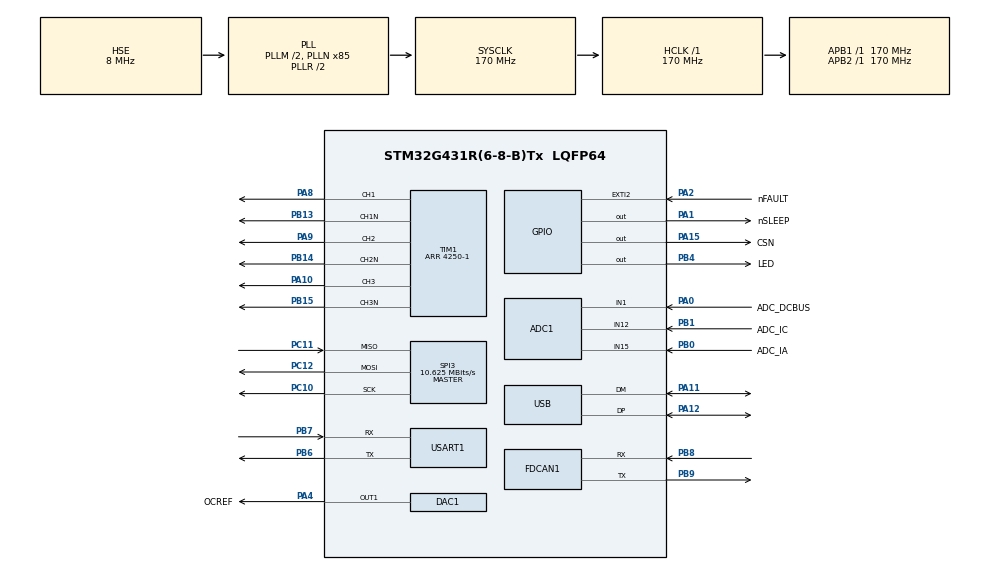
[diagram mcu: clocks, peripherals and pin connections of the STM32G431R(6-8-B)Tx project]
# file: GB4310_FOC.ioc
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ADC1.Channel-4\#ChannelRegularConversion=ADC_CHANNEL_1
ADC1.Channel-5\#ChannelRegularConversion=ADC_CHANNEL_VREFINT
ADC1.DMAContinuousRequests=ENABLE
ADC1.EOCSelection=ADC_EOC_SINGLE_CONV
ADC1.EnableInjectedConversion=ENABLE
ADC1.EnableRegularConversion=ENABLE
ADC1.ExternalTrigConv=ADC_EXTERNALTRIG_T7_TRGO
ADC1.ExternalTrigConvEdge=ADC_EXTERNALTRIGCONVEDGE_RISING
ADC1.ExternalTrigInjecConv=ADC_EXTERNALTRIGINJEC_T1_CC4
ADC1.ExternalTrigInjecConvEdge=ADC_EXTERNALTRIGINJECCONV_EDGE_FALLING
ADC1.InjNumberOfConversion=2
ADC1.InjectedChannel-1\#ChannelInjectedConversion=ADC_CHANNEL_15
ADC1.InjectedChannel-2\#ChannelInjectedConversion=ADC_CHANNEL_12
ADC1.InjectedOffsetNumber-1\#ChannelInjectedConversion=ADC_OFFSET_NONE
ADC1.InjectedOffsetNumber-2\#ChannelInjectedConversion=ADC_OFFSET_NONE
ADC1.InjectedRank-1\#ChannelInjectedConversion=1
ADC1.InjectedRank-2\#ChannelInjectedConversion=2
ADC1.InjectedSamplingTime-1\#ChannelInjectedConversion=ADC_SAMPLETIME_2CYCLES_5
ADC1.InjectedSamplingTime-2\#ChannelInjectedConversion=ADC_SAMPLETIME_2CYCLES_5
ADC1.NbrOfConversion=2
ADC1.NbrOfConversionFlag=1
ADC1.OffsetNumber-4\#ChannelRegularConversion=ADC_OFFSET_NONE
ADC1.OffsetNumber-5\#ChannelRegularConversion=ADC_OFFSET_NONE
ADC1.Rank-4\#ChannelRegularConversion=1
ADC1.Rank-5\#ChannelRegularConversion=2
ADC1.Rank1_Channel=ADC_CHANNEL_15
ADC1.SamplingTime-4\#ChannelRegularConversion=ADC_SAMPLETIME_247CYCLES_5
ADC1.SamplingTime-5\#ChannelRegularConversion=ADC_SAMPLETIME_247CYCLES_5
ADC1.master=1
CRC.CRCLength=CRC_POLYLENGTH_8B
CRC.DefaultInitValueUse=DEFAULT_INIT_VALUE_DISABLE
CRC.DefaultPolynomialUse=DEFAULT_POLYNOMIAL_DISABLE
CRC.InputDataInversionMode=CRC_INPUTDATA_INVERSION_NONE
DAC1.DAC_HighFrequency_OUT1-DAC_OUT1=DAC_HIGH_FREQUENCY_INTERFACE_MODE_AUTOMATIC
DAC1.DAC_OutputBuffer-DAC_OUT1=DAC_OUTPUTBUFFER_DISABLE
DAC1.DAC_SampleAndHold-DAC_OUT1=DAC_SAMPLEANDHOLD_DISABLE
DAC1.DAC_Trigger_OUT1-DAC_OUT1=DAC_TRIGGER_NONE
Dma.ADC1.4.Direction=DMA_PERIPH_TO_MEMORY
Dma.ADC1.4.EventEnable=DISABLE
Dma.ADC1.4.Instance=DMA1_Channel5
Dma.ADC1.4.MemDataAlignment=DMA_MDATAALIGN_HALFWORD
Dma.ADC1.4.MemInc=DMA_MINC_ENABLE
Dma.ADC1.4.Mode=DMA_CIRCULAR
Dma.ADC1.4.PeriphDataAlignment=DMA_PDATAALIGN_HALFWORD
Dma.ADC1.4.PeriphInc=DMA_PINC_DISABLE
Dma.ADC1.4.Polarity=HAL_DMAMUX_REQ_GEN_RISING
Dma.ADC1.4.Priority=DMA_PRIORITY_VERY_HIGH
Dma.ADC1.4.RequestNumber=1
Dma.ADC1.4.SignalID=NONE
Dma.ADC1.4.SyncEnable=DISABLE
Dma.ADC1.4.SyncPolarity=HAL_DMAMUX_SYNC_NO_EVENT
Dma.ADC1.4.SyncRequestNumber=1
Dma.ADC1.4.SyncSignalID=NONE
Dma.Request0=USART1_TX
Dma.Request1=USART1_RX
Dma.Request2=SPI3_TX
Dma.Request3=SPI3_RX
Dma.Request4=ADC1
Dma.SPI3_RX.3.Direction=DMA_PERIPH_TO_MEMORY
Dma.SPI3_RX.3.EventEnable=DISABLE
Dma.SPI3_RX.3.Instance=DMA1_Channel4
Dma.SPI3_RX.3.MemDataAlignment=DMA_MDATAALIGN_BYTE
Dma.SPI3_RX.3.MemInc=DMA_MINC_ENABLE
Dma.SPI3_RX.3.Mode=DMA_NORMAL
Dma.SPI3_RX.3.PeriphDataAlignment=DMA_PDATAALIGN_BYTE
Dma.SPI3_RX.3.PeriphInc=DMA_PINC_DISABLE
Dma.SPI3_RX.3.Polarity=HAL_DMAMUX_REQ_GEN_RISING
Dma.SPI3_RX.3.Priority=DMA_PRIORITY_HIGH
Dma.SPI3_RX.3.RequestNumber=1
Dma.SPI3_RX.3.SignalID=NONE
Dma.SPI3_RX.3.SyncEnable=DISABLE
Dma.SPI3_RX.3.SyncPolarity=HAL_DMAMUX_SYNC_NO_EVENT
Dma.SPI3_RX.3.SyncRequestNumber=1
Dma.SPI3_RX.3.SyncSignalID=NONE
Dma.SPI3_TX.2.Direction=DMA_MEMORY_TO_PERIPH
Dma.SPI3_TX.2.EventEnable=DISABLE
Dma.SPI3_TX.2.Instance=DMA1_Channel3
Dma.SPI3_TX.2.MemDataAlignment=DMA_MDATAALIGN_BYTE
Dma.SPI3_TX.2.MemInc=DMA_MINC_ENABLE
Dma.SPI3_TX.2.Mode=DMA_NORMAL
Dma.SPI3_TX.2.PeriphDataAlignment=DMA_PDATAALIGN_BYTE
Dma.SPI3_TX.2.PeriphInc=DMA_PINC_DISABLE
Dma.SPI3_TX.2.Polarity=HAL_DMAMUX_REQ_GEN_RISING
Dma.SPI3_TX.2.Priority=DMA_PRIORITY_HIGH
Dma.SPI3_TX.2.RequestNumber=1
Dma.SPI3_TX.2.SignalID=NONE
Dma.SPI3_TX.2.SyncEnable=DISABLE
Dma.SPI3_TX.2.SyncPolarity=HAL_DMAMUX_SYNC_NO_EVENT
Dma.SPI3_TX.2.SyncRequestNumber=1
Dma.SPI3_TX.2.SyncSignalID=NONE
Dma.USART1_RX.1.Direction=DMA_PERIPH_TO_MEMORY
Dma.USART1_RX.1.EventEnable=DISABLE
Dma.USART1_RX.1.Instance=DMA1_Channel2
Dma.USART1_RX.1.MemDataAlignment=DMA_MDATAALIGN_BYTE
Dma.USART1_RX.1.MemInc=DMA_MINC_ENABLE
Dma.USART1_RX.1.Mode=DMA_NORMAL
Dma.USART1_RX.1.PeriphDataAlignment=DMA_PDATAALIGN_BYTE
Dma.USART1_RX.1.PeriphInc=DMA_PINC_DISABLE
Dma.USART1_RX.1.Polarity=HAL_DMAMUX_REQ_GEN_RISING
Dma.USART1_RX.1.Priority=DMA_PRIORITY_LOW
Dma.USART1_RX.1.RequestNumber=1
Dma.USART1_RX.1.SignalID=NONE
Dma.USART1_RX.1.SyncEnable=DISABLE
Dma.USART1_RX.1.SyncPolarity=HAL_DMAMUX_SYNC_NO_EVENT
Dma.USART1_RX.1.SyncRequestNumber=1
Dma.USART1_RX.1.SyncSignalID=NONE
Dma.USART1_TX.0.Direction=DMA_MEMORY_TO_PERIPH
Dma.USART1_TX.0.EventEnable=DISABLE
Dma.USART1_TX.0.Instance=DMA1_Channel1
Dma.USART1_TX.0.MemDataAlignment=DMA_MDATAALIGN_BYTE
Dma.USART1_TX.0.MemInc=DMA_MINC_ENABLE
Dma.USART1_TX.0.Mode=DMA_NORMAL
Dma.USART1_TX.0.PeriphDataAlignment=DMA_PDATAALIGN_BYTE
Dma.USART1_TX.0.PeriphInc=DMA_PINC_DISABLE
Dma.USART1_TX.0.Polarity=HAL_DMAMUX_REQ_GEN_RISING
Dma.USART1_TX.0.Priority=DMA_PRIORITY_LOW
Dma.USART1_TX.0.RequestNumber=1
Dma.USART1_TX.0.SignalID=NONE
Dma.USART1_TX.0.SyncEnable=DISABLE
Dma.USART1_TX.0.SyncPolarity=HAL_DMAMUX_SYNC_NO_EVENT
Dma.USART1_TX.0.SyncRequestNumber=1
Dma.USART1_TX.0.SyncSignalID=NONE
FDCAN1.CalculateBaudRateNominal=3541666
FDCAN1.CalculateTimeBitNominal=282
FDCAN1.CalculateTimeQuantumNominal=94.11764705882354
Mcu.Family=STM32G4
Mcu.Name=STM32G431R(6-8-B)Tx
Mcu.Package=LQFP64
NVIC.ADC1_2_IRQn=true\:1\:0\:true\:false\:true\:true\:true\:true
NVIC.DMA1_Channel3_IRQn=true\:4\:0\:true\:false\:true\:false\:true\:true
NVIC.DMA1_Channel4_IRQn=true\:4\:0\:true\:false\:true\:false\:true\:true
NVIC.DMA1_Channel5_IRQn=true\:2\:0\:true\:false\:true\:true\:true\:true
NVIC.EXTI2_IRQn=true\:0\:0\:false\:false\:true\:true\:true\:true
NVIC.PriorityGroup=NVIC_PRIORITYGROUP_4
NVIC.TIM1_CC_IRQn=true\:4\:0\:true\:false\:true\:true\:true\:true
NVIC.TIM1_UP_TIM16_IRQn=true\:3\:0\:true\:false\:true\:true\:true\:true
NVIC.TIM7_IRQn=true\:5\:0\:true\:false\:true\:true\:true\:true
NVIC.USB_LP_IRQn=true\:6\:0\:true\:false\:true\:false\:true\:true
PA0.GPIO_Label=ADC_DCBUS
PA0.Mode=IN1-Single-Ended
PA0.Signal=ADC1_IN1
PA1.GPIO_Label=nSLEEP
PA1.GPIO_PuPd=GPIO_NOPULL
PA1.PinState=GPIO_PIN_RESET
PA1.Signal=GPIO_Output
PA10.Signal=S_TIM1_CH3
PA11.Mode=Device
PA11.Signal=USB_DM
PA12.Mode=Device
PA12.Signal=USB_DP
PA13.Mode=Serial_Wire
PA13.Signal=SYS_JTMS-SWDIO
PA14.Mode=Serial_Wire
PA14.Signal=SYS_JTCK-SWCLK
PA15.GPIO_Label=CSN
PA15.GPIO_PuPd=GPIO_PULLUP
PA15.PinState=GPIO_PIN_SET
PA15.Signal=GPIO_Output
PA2.GPIO_Label=nFAULT
PA2.GPIO_ModeDefaultEXTI=GPIO_MODE_IT_FALLING
PA2.GPIO_PuPd=GPIO_PULLUP
PA2.Signal=GPXTI2
PA4.GPIO_Label=OCREF
PA4.Signal=COMP_DAC11_group
PA8.Signal=S_TIM1_CH1
PA9.Signal=S_TIM1_CH2
PB0.GPIO_Label=ADC_IA
PB0.Mode=IN15-Single-Ended
PB0.Signal=ADC1_IN15
PB1.GPIO_Label=ADC_IC
PB1.Mode=IN12-Single-Ended
PB1.Signal=ADC1_IN12
PB13.Mode=PWM Generation1 CH1 CH1N
PB13.Signal=TIM1_CH1N
PB14.Mode=PWM Generation2 CH2 CH2N
PB14.Signal=TIM1_CH2N
PB15.Mode=PWM Generation3 CH3 CH3N
PB15.Signal=TIM1_CH3N
PB4.GPIO_Label=LED
PB4.PinState=GPIO_PIN_SET
PB4.Signal=GPIO_Output
PB6.Mode=Asynchronous
PB6.Signal=USART1_TX
PB7.Mode=Asynchronous
PB7.Signal=USART1_RX
PB8-BOOT0.Mode=FDCAN_Activate
PB8-BOOT0.Signal=FDCAN1_RX
PB9.Mode=FDCAN_Activate
PB9.Signal=FDCAN1_TX
PC10.Mode=Full_Duplex_Master
PC10.Signal=SPI3_SCK
PC11.Mode=Full_Duplex_Master
PC11.Signal=SPI3_MISO
PC12.Mode=Full_Duplex_Master
PC12.Signal=SPI3_MOSI
PF0-OSC_IN.Mode=HSE-External-Oscillator
PF0-OSC_IN.Signal=RCC_OSC_IN
PF1-OSC_OUT.Mode=HSE-External-Oscillator
PF1-OSC_OUT.Signal=RCC_OSC_OUT
ProjectManager.HeapSize=0x200
ProjectManager.StackSize=0x400
ProjectManager.TargetToolchain=CMake
RCC.ADC12Freq_Value=170000000
RCC.AHBFreq_Value=170000000
RCC.APB1Freq_Value=170000000
RCC.APB1TimFreq_Value=170000000
RCC.APB2Freq_Value=170000000
RCC.APB2TimFreq_Value=170000000
RCC.CK48CLockSelection=RCC_USBCLKSOURCE_HSI48
RCC.CortexFreq_Value=170000000
RCC.EXTERNAL_CLOCK_VALUE=12288000
RCC.HCLKFreq_Value=170000000
RCC.HSE_VALUE=8000000
RCC.HSI48_VALUE=48000000
RCC.HSI_VALUE=16000000
RCC.LSE_VALUE=32768
RCC.PLLM=RCC_PLLM_DIV2
RCC.PLLN=85
RCC.PLLSourceVirtual=RCC_PLLSOURCE_HSE
RCC.SYSCLKFreq_VALUE=170000000
RCC.SYSCLKSource=RCC_SYSCLKSOURCE_PLLCLK
RCC.USBFreq_Value=48000000
RCC.VCOOutputFreq_Value=340000000
SH.COMP_DAC11_group.0=DAC1_OUT1,DAC_OUT1
SH.S_TIM1_CH1.0=TIM1_CH1,PWM Generation1 CH1 CH1N
SH.S_TIM1_CH2.0=TIM1_CH2,PWM Generation2 CH2 CH2N
SH.S_TIM1_CH3.0=TIM1_CH3,PWM Generation3 CH3 CH3N
SPI3.BaudRatePrescaler=SPI_BAUDRATEPRESCALER_16
SPI3.CLKPhase=SPI_PHASE_2EDGE
SPI3.CLKPolarity=SPI_POLARITY_HIGH
SPI3.CRCCalculation=SPI_CRCCALCULATION_DISABLE
SPI3.CalculateBaudRate=10.625 MBits/s
SPI3.DataSize=SPI_DATASIZE_8BIT
SPI3.Direction=SPI_DIRECTION_2LINES
SPI3.Mode=SPI_MODE_MASTER
SPI3.TIMode=SPI_TIMODE_DISABLE
SPI3.VirtualType=VM_MASTER
TIM1.AutoReloadPreload=TIM_AUTORELOAD_PRELOAD_DISABLE
TIM1.Channel-PWM\ Generation1\ CH1\ CH1N=TIM_CHANNEL_1
TIM1.Channel-PWM\ Generation2\ CH2\ CH2N=TIM_CHANNEL_2
TIM1.Channel-PWM\ Generation3\ CH3\ CH3N=TIM_CHANNEL_3
TIM1.Channel-PWM\ Generation4\ No\ Output=TIM_CHANNEL_4
TIM1.CounterMode=TIM_COUNTERMODE_CENTERALIGNED1
TIM1.DeadTime=0
TIM1.OCMode_PWM-PWM\ Generation1\ CH1\ CH1N=TIM_OCMODE_PWM1
TIM1.OCMode_PWM-PWM\ Generation3\ CH3\ CH3N=TIM_OCMODE_PWM1
TIM1.OCMode_PWM-PWM\ Generation4\ No\ Output=TIM_OCMODE_PWM1
TIM1.PeriodNoDither=4250-1
TIM1.RepetitionCounter=1
TIM1.TIM_MasterOutputTrigger=TIM_TRGO_RESET
TIM1.TIM_MasterOutputTrigger2=TIM_TRGO2_RESET
TIM7.AutoReloadPreload=TIM_AUTORELOAD_PRELOAD_ENABLE
TIM7.PeriodNoDither=1000-1
TIM7.Prescaler=170-1
TIM7.TIM_MasterOutputTrigger=TIM_TRGO_UPDATE
USART1.VirtualMode-Asynchronous=VM_ASYNC
USB.Sof_enable=DISABLE
USB_DEVICE.APP_RX_DATA_SIZE=512
USB_DEVICE.APP_TX_DATA_SIZE=1024
USB_DEVICE.CLASS_NAME_FS=CDC
USB_DEVICE.USBD_LPM_ENABLED=1
USB_DEVICE.USBD_MAX_STR_DESC_SIZ=512
USB_DEVICE.VirtualMode=Cdc
USB_DEVICE.VirtualModeFS=Cdc_FS
VP_ADC1_Vref_Input.Mode=IN-Vrefint
VP_CORDIC_VS_CORDIC.Mode=CORDIC_Activate
VP_CRC_VS_CRC.Mode=CRC_Activate
VP_RCC_VS_USB.Mode=USB_FS
VP_SYS_VS_DBSignals.Mode=DisableDeadBatterySignals
VP_TIM1_VS_ClockSourceINT.Mode=Internal
VP_TIM1_VS_no_output4.Mode=PWM Generation4 No Output
VP_TIM7_VS_ClockSourceINT.Mode=Enable_Timer
VP_USB_DEVICE_VS_USB_DEVICE_CDC_FS.Mode=CDC_FS
board=custom

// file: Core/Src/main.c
/* USER CODE BEGIN Header */
/**
  ******************************************************************************
  * @file           : main.c
  * @brief          : Main program body
  ******************************************************************************
  * @attention
  *
  * Copyright (c) 2026 STMicroelectronics.
  * All rights reserved.
  *
  * This software is licensed under terms that can be found in the LICENSE file
  * in the root directory of this software component.
  * If no LICENSE file comes with this software, it is provided AS-IS.
  *
  ******************************************************************************
  */
/* USER CODE END Header */
#include "main.h"
#include "adc.h"
#include "cordic.h"
#include "crc.h"
#include "dac.h"
#include "dma.h"
#include "fdcan.h"
#include "spi.h"
#include "stm32g4xx_hal.h"
#include "tim.h"
#include "usart.h"
#include "usb_device.h"
#include "gpio.h"

/* USER CODE BEGIN Includes */
#include "System.h"
#include "USB.h"
/* USER CODE END Includes */

void SystemClock_Config(void);

int main(void)
{

  /* MCU Configuration--------------------------------------------------------*/

  /* Reset of all peripherals, Initializes the Flash interface and the Systick. */
  HAL_Init();

  /* Configure the system clock */
  SystemClock_Config();

  /* USER CODE BEGIN SysInit */
  /* USB 环形缓冲区先就绪, 再初始化 USB 设备, 避免枚举期间的接收数据落到未初始化缓冲区 */
  USB_Init();
  /* USER CODE END SysInit */

  /* Initialize all configured peripherals */
  MX_GPIO_Init();
  MX_DMA_Init();
  MX_FDCAN1_Init();
  MX_ADC1_Init();
  MX_DAC1_Init();
  MX_SPI3_Init();
  MX_TIM1_Init();
  MX_USART1_UART_Init();
  MX_CRC_Init();
  MX_CORDIC_Init();
  MX_USB_Device_Init();
  MX_TIM7_Init();
  /* USER CODE BEGIN 2 */
  /* BSP 模块初始化: FOC → 栅极驱动 → ADC 采样 → 编码器 → PID 三环 */
  System_Init();
  /* USER CODE END 2 */

  /* Infinite loop */
  /* USER CODE BEGIN WHILE */
  while (1)
  {
    /* 空闲任务: 命令解析 + 遥测发送 (均为非阻塞) */
    USB_Command_Process();
    USB_TxProcess();
    /* USER CODE END WHILE */

  }
}

void SystemClock_Config(void)
{
  RCC_OscInitTypeDef RCC_OscInitStruct = {0};
  RCC_ClkInitTypeDef RCC_ClkInitStruct = {0};
  RCC_CRSInitTypeDef pInit = {0};

  /** Configure the main internal regulator output voltage
  */
  HAL_PWREx_ControlVoltageScaling(PWR_REGULATOR_VOLTAGE_SCALE1_BOOST);

  /** Initializes the RCC Oscillators according to the specified parameters
  * in the RCC_OscInitTypeDef structure.
  */
  RCC_OscInitStruct.OscillatorType = RCC_OSCILLATORTYPE_HSI48|RCC_OSCILLATORTYPE_HSE;
  RCC_OscInitStruct.HSEState = RCC_HSE_ON;
  RCC_OscInitStruct.HSI48State = RCC_HSI48_ON;
  RCC_OscInitStruct.PLL.PLLState = RCC_PLL_ON;
  RCC_OscInitStruct.PLL.PLLSource = RCC_PLLSOURCE_HSE;
  RCC_OscInitStruct.PLL.PLLM = RCC_PLLM_DIV2;
  RCC_OscInitStruct.PLL.PLLN = 85;
  RCC_OscInitStruct.PLL.PLLP = RCC_PLLP_DIV2;
  RCC_OscInitStruct.PLL.PLLQ = RCC_PLLQ_DIV2;
  RCC_OscInitStruct.PLL.PLLR = RCC_PLLR_DIV2;
  if (HAL_RCC_OscConfig(&RCC_OscInitStruct) != HAL_OK)
  {
    Error_Handler();
  }

  /** Initializes the CPU, AHB and APB buses clocks
  */
  RCC_ClkInitStruct.ClockType = RCC_CLOCKTYPE_HCLK|RCC_CLOCKTYPE_SYSCLK
                              |RCC_CLOCKTYPE_PCLK1|RCC_CLOCKTYPE_PCLK2;
  RCC_ClkInitStruct.SYSCLKSource = RCC_SYSCLKSOURCE_PLLCLK;
  RCC_ClkInitStruct.AHBCLKDivider = RCC_SYSCLK_DIV1;
  RCC_ClkInitStruct.APB1CLKDivider = RCC_HCLK_DIV1;
  RCC_ClkInitStruct.APB2CLKDivider = RCC_HCLK_DIV1;

  if (HAL_RCC_ClockConfig(&RCC_ClkInitStruct, FLASH_LATENCY_4) != HAL_OK)
  {
    Error_Handler();
  }

  /** Enable the SYSCFG APB clock
  */
  __HAL_RCC_CRS_CLK_ENABLE();

  /** Configures CRS
  */
  pInit.Prescaler = RCC_CRS_SYNC_DIV1;
  pInit.Source = RCC_CRS_SYNC_SOURCE_USB;
  pInit.Polarity = RCC_CRS_SYNC_POLARITY_RISING;
  pInit.ReloadValue = __HAL_RCC_CRS_RELOADVALUE_CALCULATE(48000000,1000);
  pInit.ErrorLimitValue = 34;
  pInit.HSI48CalibrationValue = 32;

  HAL_RCCEx_CRSConfig(&pInit);
}

void Error_Handler(void)
{
  __disable_irq();
  while (1)
  {
  }
}
